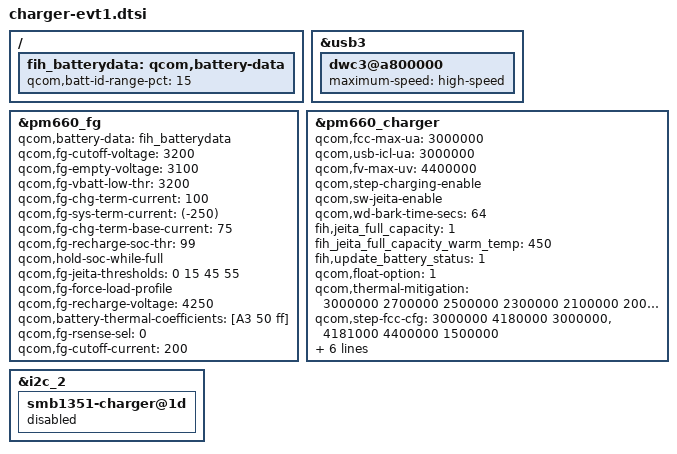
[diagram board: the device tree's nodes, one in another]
/ {
	/delete-node/ qcom,battery-data;
	fih_batterydata: qcom,battery-data {
		qcom,batt-id-range-pct = <15>;
		#include "fg-gen3-batterydata-ALT-3000mah-100k.dtsi"
		#include "fg-gen3-batterydata-coslight-3000mah-68k.dtsi"
		#include "fg-gen3-batterydata-fake-3000mah-39k.dtsi"
		#include "fg-gen3-batterydata-XF-3000mah-300k.dtsi"
		#include "fg-gen3-batterydata-coslight-3000mah-200k.dtsi"
	//	#include "fg-gen3-batterydata-unkown-3000mah-ffffk.dtsi"
	};
};

&usb3 {
	dwc3@a800000 {
		maximum-speed = "high-speed";
	};
};

&pm660_fg {
	qcom,battery-data = <&fih_batterydata>;
	qcom,fg-cutoff-voltage = <3200>;
	qcom,fg-empty-voltage = <3100>;
	qcom,fg-vbatt-low-thr = <3200>;
	qcom,fg-chg-term-current = <100>;	/* 100mA > 0.02C */
	qcom,fg-sys-term-current = <(-250)>;	/* 100mA + 25mA */
	qcom,fg-chg-term-base-current = <75>;	/* 100mA - 25mA */
	qcom,fg-recharge-soc-thr = <99>;
	//qcom,fg-auto-recharge-soc; // ida disable the SOC-base recharge function
	qcom,hold-soc-while-full;
	qcom,fg-jeita-thresholds = <0 15 45 55>;
	qcom,fg-force-load-profile;
	qcom,fg-recharge-voltage = <4250>;
	qcom,battery-thermal-coefficients = [A3 50 ff];
	qcom,fg-rsense-sel = <0>;
	qcom,fg-cutoff-current = <200>; //default: 500mA
};

&pm660_charger {
	/delete-property/ qcom,batteryless-platform;
	//qcom,auto-recharge-soc;//
	qcom,fcc-max-ua = <3000000>;
	qcom,usb-icl-ua = <3000000>;
	qcom,fv-max-uv = <4400000>;
	/delete-property/ qcom,wipower-max-uw;
	qcom,step-charging-enable;
	qcom,sw-jeita-enable;
	qcom,wd-bark-time-secs = <64>;
//	qcom,step-soc-thresholds = <50 55 60 63>;
//	qcom,step-current-deltas = <1500000 0 0 0 0>;
	fih,jeita_full_capacity = <1>;
	fih_jeita_full_capacity_warm_temp = <450>;
	fih,update_battery_status = <1>;
	qcom,float-option = <1>;
//	qcom,jeita-fv-comp-cool = <0>;		/* 4.4V = 4.4V - 0.0V */
//	qcom,jeita-cc-comp-cool = <900000>;	/* 600mA = 1500mA - 900mA */
//	qcom,jeita-fv-comp-warm = <300000>;	/* 4.1V = 4.4V - 0.3V */
//	qcom,jeita-cc-comp-warm = <600000>;	/* 900mA = 1500mA - 600mA */
	qcom,thermal-mitigation = <3000000 2700000 2500000 2300000 2100000 2000000
		1600000 1200000 1000000 700000 600000 500000 100000 0>;
/* VBAT_LOW	VBAT_HIGH	FCC */
	qcom,step-fcc-cfg = <3000000 4180000 3000000>,
					<4181000 4400000 1500000>;
/* TEMP_LOW	TEMP_HIGH	FCC */
	qcom,jeita-fcc-cfg = <0 157 600000>,
					<158 440 3000000>,
					<441 550 900000>;
/* TEMP_LOW	TEMP_HIGH	FV */
	qcom,jeita-fv-cfg = <0 157 4400000>,
					<158 440 4400000>,
					<441 550 4100000>;
	qcom,step-fcc-hysteresis = <20000>;
	qcom,jeita-fcc-fv-hysteresis = <6>;
};

&i2c_2 {
	smb1351-charger@1d {
		status = "disabled";
	};
};
